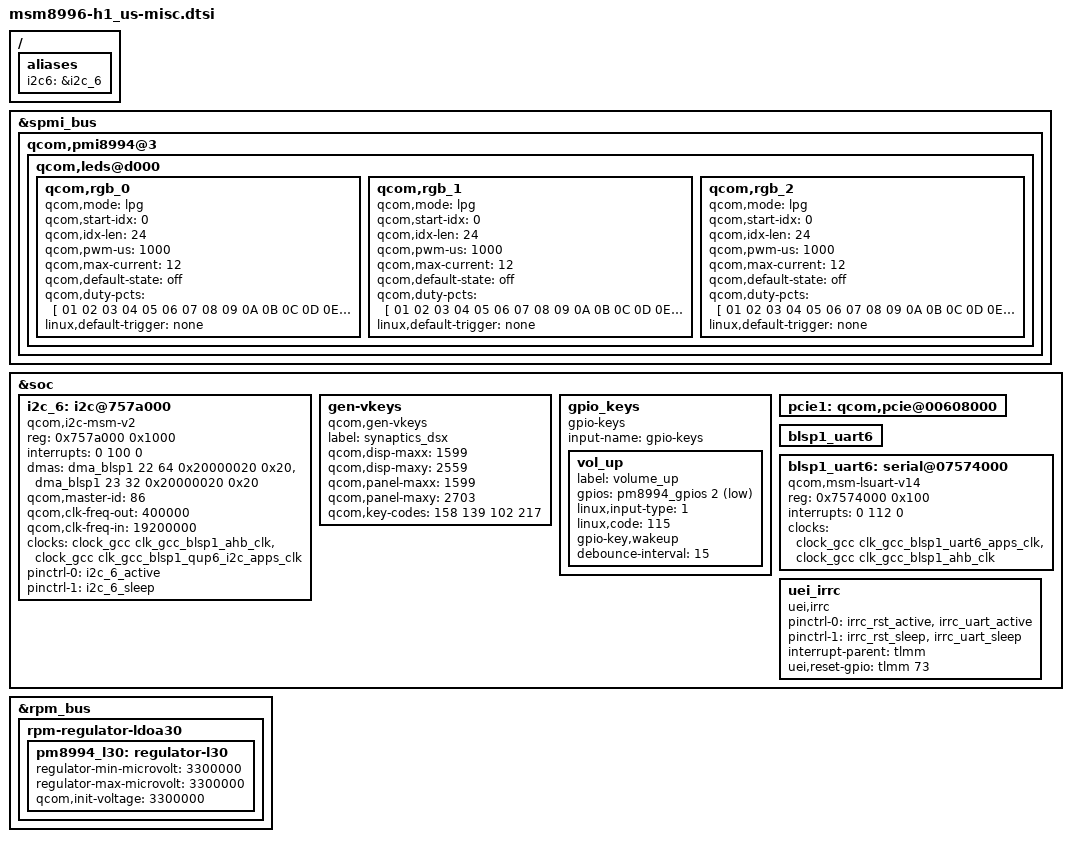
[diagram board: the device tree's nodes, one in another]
/* Copyright (c) 2015, The Linux Foundation. All rights reserved.
 *
 * This program is free software; you can redistribute it and/or modify
 * it under the terms of the GNU General Public License version 2 and
 * only version 2 as published by the Free Software Foundation.
 *
 * This program is distributed in the hope that it will be useful,
 * but WITHOUT ANY WARRANTY; without even the implied warranty of
 * MERCHANTABILITY or FITNESS FOR A PARTICULAR PURPOSE.  See the
 * GNU General Public License for more details.
 */

/{
	aliases {
		i2c6 = &i2c_6;
	};
};

/* LED setting */
&spmi_bus {
	qcom,pmi8994@3 {
		qcom,leds@d000 {
			status = "okay";
			qcom,rgb_0 {
				qcom,mode = "lpg";
				qcom,start-idx = <0>;
				qcom,idx-len = <24>;
				qcom,pwm-us = <1000>;
				qcom,max-current = <12>;
				qcom,default-state = "off";
				qcom,duty-pcts = [
					 01 02 03 04 05 06 07 08
					 09 0A 0B 0C 0D 0E 0F 10
					 11 12 13 14 15 16 17 18
					 ];
				linux,default-trigger = "none";
			};

			qcom,rgb_1 {
				qcom,mode = "lpg";
				qcom,start-idx = <0>;
				qcom,idx-len = <24>;
				qcom,pwm-us = <1000>;
				qcom,max-current = <12>;
				qcom,default-state = "off";
				qcom,duty-pcts = [
					 01 02 03 04 05 06 07 08
					 09 0A 0B 0C 0D 0E 0F 10
					 11 12 13 14 15 16 17 18
					 ];
				linux,default-trigger = "none";
			};

			qcom,rgb_2 {
				qcom,mode = "lpg";
				qcom,start-idx = <0>;
				qcom,idx-len = <24>;
				qcom,pwm-us = <1000>;
				qcom,max-current = <12>;
				qcom,default-state = "off";
				qcom,duty-pcts = [
					 01 02 03 04 05 06 07 08
					 09 0A 0B 0C 0D 0E 0F 10
					 11 12 13 14 15 16 17 18
					 ];
				linux,default-trigger = "none";
			};
		};
	};
};
&soc {
	i2c_6: i2c@757a000 { /* BLSP1 QUP6 */
		compatible = "qcom,i2c-msm-v2";
		#address-cells = <1>;
		#size-cells = <0>;
		reg-names = "qup_phys_addr";
		reg = <0x757a000 0x1000>;
		interrupt-names = "qup_irq";
		interrupts = <0 100 0>;
		dmas = <&dma_blsp1 22 64 0x20000020 0x20>,
				<&dma_blsp1 23 32 0x20000020 0x20>;
		dma-names = "tx", "rx";
		qcom,master-id = <86>;
		qcom,clk-freq-out = <400000>;
		qcom,clk-freq-in  = <19200000>;
		clock-names = "iface_clk", "core_clk";
		clocks = <&clock_gcc clk_gcc_blsp1_ahb_clk>,
			 <&clock_gcc clk_gcc_blsp1_qup6_i2c_apps_clk>;
		pinctrl-names = "i2c_active", "i2c_sleep";
		pinctrl-0 = <&i2c_6_active>;
		pinctrl-1 = <&i2c_6_sleep>;
	};

	gen-vkeys {
		compatible = "qcom,gen-vkeys";
		label = "synaptics_dsx";
		qcom,disp-maxx = <1599>;
		qcom,disp-maxy = <2559>;
		qcom,panel-maxx = <1599>;
		qcom,panel-maxy = <2703>;
		qcom,key-codes = <158 139 102 217>;
	};

	gpio_keys {
		compatible = "gpio-keys";
		input-name = "gpio-keys";

		vol_up {
			label = "volume_up";
			gpios = <&pm8994_gpios 2 0x1>;
			linux,input-type = <1>;
			linux,code = <115>;
			gpio-key,wakeup;
			debounce-interval = <15>;
		};
	};

	pcie1: qcom,pcie@00608000 {
		/delete-property/ perst-gpio;
		/delete-property/ wake-gpio;
	};

        blsp1_uart6 {
                status = "ok";
        };

    blsp1_uart6:serial@07574000 {
        compatible = "qcom,msm-lsuart-v14";
        reg = <0x7574000 0x100>;
        interrupts = <0 112 0>;
        status = "ok";
        clock-names = "core_clk", "iface_clk";
        clocks = <&clock_gcc clk_gcc_blsp1_uart6_apps_clk>,
        <&clock_gcc clk_gcc_blsp1_ahb_clk>;
    };

	uei_irrc {
		compatible = "uei,irrc";
		status = "ok";
		pinctrl-names = "default", "sleep";
		pinctrl-0 = <&irrc_rst_active &irrc_uart_active>;
		pinctrl-1 = <&irrc_rst_sleep &irrc_uart_sleep>;
		interrupt-parent = <&tlmm>;
		uei,reset-gpio = <&tlmm 73 0x00>;
	};
};

&rpm_bus {
	rpm-regulator-ldoa30 {
		status = "okay";
		pm8994_l30: regulator-l30 {
			regulator-min-microvolt = <3300000>;
			regulator-max-microvolt = <3300000>;
			qcom,init-voltage = <3300000>;
			status = "okay";
		};
	};
};
